# MWPR1516 register map
Vendor: Freescale Semiconductor, Inc.; Series: Kinetis; File version: 1.6
CPU: CM0PLUS r0p0, little endian, no MPU, no FPU, VTOR, 2 interrupt priority bits
Registers are 8-bit, read-write, reset 0x0 unless marked. A register's access mark holds for its fields unless they carry their own. Offsets are from the block's base; [hi:lo] are bit positions; {n}, {i} and the like mark numbered series.

## SIM — System Integration Module
Base 0x40048000; register names take the prefix SIM_
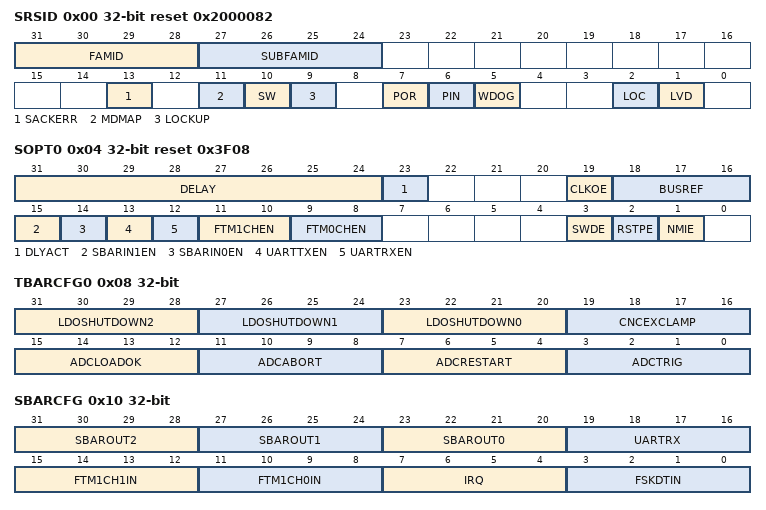
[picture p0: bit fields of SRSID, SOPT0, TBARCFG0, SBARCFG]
0x00 SRSID 32-bit ro reset 0x2000082 — System Reset Status and ID Register
  [31:28] FAMID — Wireless power controller Family ID
    0=Wireless power receiver (WPR); 1=Wireless charger receiver (WCR); 8=Wireless charger transmitter (WCT)
  [27:24] SUBFAMID — Wireless power controller Sub-family power ID
    0=1 W; 1=5 W; 2=15 W
  [13] SACKERR — Stop Mode Acknowledge Error Reset
    0=Reset is not caused by peripheral failure to acknowledge attempt to enter Stop mode; 1=Reset is caused by peripheral failure to acknowledge attempt to enter Stop mode
  [11] MDMAP — MDM-AP System Reset Request
    0=Reset is not caused by the host debugger system setting of the System Reset Request field; 1=Reset is caused by the host debugger system setting of the System Reset Request field
  [10] SW — Software
    0=Reset is not caused by software setting of the SYSRESETREQ bit; 1=Reset caused by software setting of the SYSRESETREQ bit
  [9] LOCKUP — Core Lockup
    0=Reset is not caused by core LOCKUP event; 1=Reset is caused by core LOCKUP event
  [7] POR — Power-on Reset
    0=Reset not caused by POR; 1=POR-caused reset
  [6] PIN — External Reset Pin
    0=Reset is not caused by external reset pin; 1=Reset originates from external reset pin
  [5] WDOG — Watchdog (WDOG)
    0=Reset is not caused by WDOG timeout; 1=Reset is caused by WDOG timeout
  [2] LOC — Internal Clock Source (ICS) Module Reset
    0=Reset is not caused by the ICS module; 1=Reset is caused by the ICS module
  [1] LVD — Low Voltage Detection
    0=Reset is not caused by LVD trip or POR; 1=Reset is caused by LVD trip or POR
0x04 SOPT0 32-bit reset 0x3F08 — System Options Register 0
  [31:24] DELAY — ADC external Trigger Delay
  [23] DLYACT ro — ADC external Trigger Delay Active
    0=The delay is inactive; 1=The delay is active
  [19] CLKOE — Bus Clock Output Enable
    0=Bus clock output is disabled on PTA2; 1=Bus clock output is enabled on PTA2
  [18:16] BUSREF — BUS Clock Output select
    0=Bus; 1=Bus divided by 2; 2=Bus divided by 4; 3=Bus divided by 8; 4=Bus divided by 16; 5=Bus divided by 32; 6=Bus divided by 64; 7=Bus divided by 128
  [15] SBARIN1EN
    0=SBAR_IN1 on PTA0 is disabled; 1=SBAR_IN1 on PTA0 is enabled
  [14] SBARIN0EN
    0=SBAR_IN0 on PTB1 is disabled; 1=SBAR_IN0 on PTB1 is enabled
  [13] UARTTXEN
    0=UART0_TX on PTA7 is disabled; 1=UART0_TX on PTA7 is enabled
  [12] UARTRXEN
    0=UART0_RX on PTA6 is disabled; 1=UART0_RX on PTA6 is enabled
  [11:10] FTM1CHEN — FTM1 Channel mapping Enable
  [9:8] FTM0CHEN — FTM0 Channel mapping Enable
  [3] SWDE — Single Wire Debug port pin mapping Enable
    0=SWDIO pin mapping on PTA4 is disabled, and SWCLK pin mapping on PTA5 is disabled; 1=PTA4 as SWDIO function, and PTA5 as SWCLK function
  [2] RSTPE — RESET Pin mapping Enable
    0=RESET pin mapping is disabled on PTB0; 1=PTB0 pin functions as RESET
  [1] NMIE — NMI pin mapping Enable
    0=NMIE pin mapping is disabled on PTB0; 1=PTB0 pin functions as NMI, when RSTPE = 0
0x08 TBARCFG0 32-bit — Trigger Crossbar Configuration Register 0
  [31:28] LDOSHUTDOWN2 — LDO external Shutdown source 2
  [27:24] LDOSHUTDOWN1 — LDO external Shutdown source 1
  [23:20] LDOSHUTDOWN0 — LDO external Shutdown source 0
  [19:16] CNCEXCLAMP — CNC External Clamp source selection
  [15:12] ADCLOADOK — ADC LoadOK source selection
  [11:8] ADCABORT — ADC sequence Abort source selection
  [7:4] ADCRESTART — ADC Restart source selection
  [3:0] ADCTRIG — ADC Trigger source selection
0x0C TBARCFG1 32-bit — Trigger Crossbar Configuration Register 1
  [3:0] TBAROUT — TBAR_OUT source selection
0x10 SBARCFG 32-bit — Signal Crossbar Configuration Register
  [31:28] SBAROUT2 — SBAR_OUT2 source selection
  [27:24] SBAROUT1 — SBAR_OUT1 source selection
  [23:20] SBAROUT0 — SBAR_OUT0 source selection
  [19:16] UARTRX — UART_RxD source selection
  [15:12] FTM1CH1IN — FTM1_CH1 Input source selection
  [11:8] FTM1CH0IN — FTM1_CH0 Input source selection
  [7:4] IRQ — IRQ input source selection
  [3:0] FSKDTIN — FSKDT Input source selection
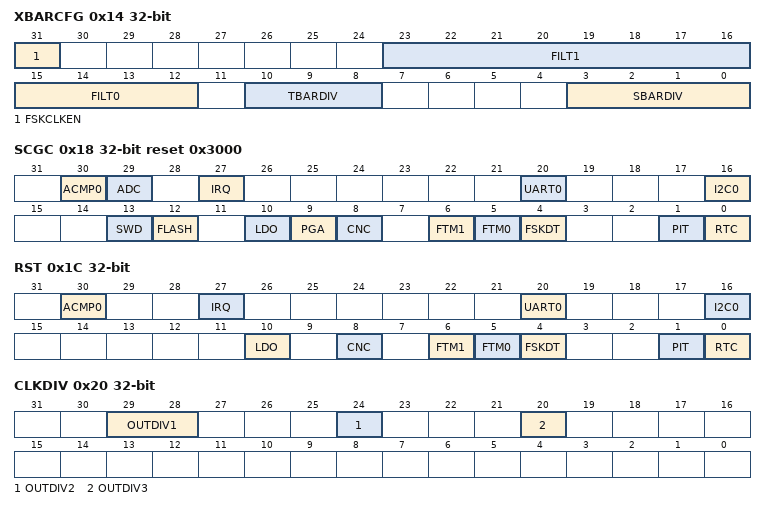
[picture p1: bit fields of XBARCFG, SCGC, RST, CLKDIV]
0x14 XBARCFG 32-bit — FSK Configuration Register
  [31] FSKCLKEN — FSK glitch filter and divider Clock Enable control
    0=Disables the FSK filter/divider clock; 1=Enables the FSK filter/divider clock
  [23:16] FILT1 — The second glitch filter width configuration control
  [15:12] FILT0 — The first glitch filter width configuration control
  [10:8] TBARDIV — TBAR FSK Divider source control
  [3:0] SBARDIV — SBAR FSK Divider source control
0x18 SCGC 32-bit reset 0x3000 — System Clock Gating Control Register
  [30] ACMP0 — ACMP0 Clock Gating Control
    0=Bus clock to the ACMP0 module is disabled; 1=Bus clock to the ACMP0 module is enabled
  [29] ADC — ADC Clock Gating Control
    0=Bus clock to the ADC module is disabled; 1=Bus clock to the ADC module is enabled
  [27] IRQ — IRQ Clock Gating Control
    0=Bus clock to the IRQ module is disabled; 1=Bus clock to the IRQ module is enabled
  [20] UART0 — UART0 Clock Gating Control
    0=Bus clock to the UART0 module is disabled; 1=Bus clock to the UART0 module is enabled
  [16] I2C0 — I2C0 Clock Gating Control
    0=Bus clock to the I2C0 module is disabled; 1=Bus clock to the I2C0 module is enabled
  [13] SWD — Single Wire Debugger (SWD) Clock Gating Control
    0=Bus clock to the SWD module is disabled; 1=Bus clock to the SWD module is enabled
  [12] FLASH — Flash Clock Gating Control
    0=Bus clock to the Flash module is disabled; 1=Bus clock to the Flash module is enabled
  [10] LDO — LDO Clock Gating Control
    0=Bus clock to the LDO module is disabled; 1=Bus clock to the LDO module is enabled
  [9] PGA — PGA Clock Gating Control
    0=Bus clock to the PGA module is disabled; 1=Bus clock to the PGA module is enabled
  [8] CNC — CNC Clock Gating Control
    0=Bus clock to the CNC module is disabled; 1=Bus clock to the CNC module is enabled
  [6] FTM1 — FTM1 Clock Gating Control
    0=Bus clock to the FTM1 module is disabled; 1=Bus clock to the FTM1 module is enabled
  [5] FTM0 — FTM0 Clock Gating Control
    0=Bus clock to the FTM0 module is disabled; 1=Bus clock to the FTM0 module is enabled
  [4] FSKDT — FSKDT Clock Gating Control
    0=Bus clock to the FSKDT module is disabled; 1=Bus clock to the FSKDT module is enabled
  [1] PIT — PIT Clock Gating Control
    0=Bus clock to the PIT module is disabled; 1=Bus clock to the PIT module is enabled
  [0] RTC — RTC Clock Gating Control
    0=Bus clock to the RTC module is disabled; 1=Bus clock to the RTC module is enabled
0x1C RST 32-bit — Reset control Register
  [30] ACMP0 — ACMP0 Reset Control
    0=Reset to the ACMP0 module is disabled; 1=Reset to the ACMP0 module is enabled
  [27] IRQ — IRQ Reset Control
    0=Reset to the IRQ module is disabled; 1=Reset to the IRQ module is enabled
  [20] UART0 — UART0 Reset Control
    0=Reset to the UART0 module is disabled; 1=Reset to the UART0 module is enabled
  [16] I2C0 — I2C0 Reset Control
    0=Reset to the I2C0 module is disabled; 1=Reset to the I2C0 module is enabled
  [10] LDO — LDO Reset Control
    0=Reset to the LDO module is disabled; 1=Reset to the LDO module is enabled
  [8] CNC — CNC Reset Control
    0=Reset to the CNC module is disabled; 1=Reset to the CNC module is enabled
  [6] FTM1 — FTM1 Reset Control
    0=Reset to the FTM1 module is disabled; 1=Reset to the FTM1 module is enabled
  [5] FTM0 — FTM0 Reset Control
    0=Reset to the FTM0 module is disabled; 1=Reset to the FTM0 module is enabled
  [4] FSKDT — FSKDT Reset Control
    0=Reset to the FSKDT module is disabled; 1=Reset to the FSKDT module is enabled
  [1] PIT — PIT Reset Control
    0=Reset to the PIT module is disabled; 1=Reset to the PIT module is enabled
  [0] RTC — RTC Reset Control
    0=Reset to the RTC module is disabled; 1=Reset to the RTC module is enabled
0x20 CLKDIV 32-bit — Clock Divider Register
  [29:28] OUTDIV1 — Clock 1 Output Divider value
    0=Same as ICSOUTCLK; 1=ICSOUTCLK is divided by 2; 2=ICSOUTCLK is divided by 3; 3=ICSOUTCLK is divided by 4
  [24] OUTDIV2 — Clock 2 Output Divider value
    0=Not divided from Divider1; 1=Divided by 2 from Divider1
  [20] OUTDIV3 — Clock 3 Output Divider value
    0=Same as ICSOUTCLK; 1=ICSOUTCLK is divided by 2
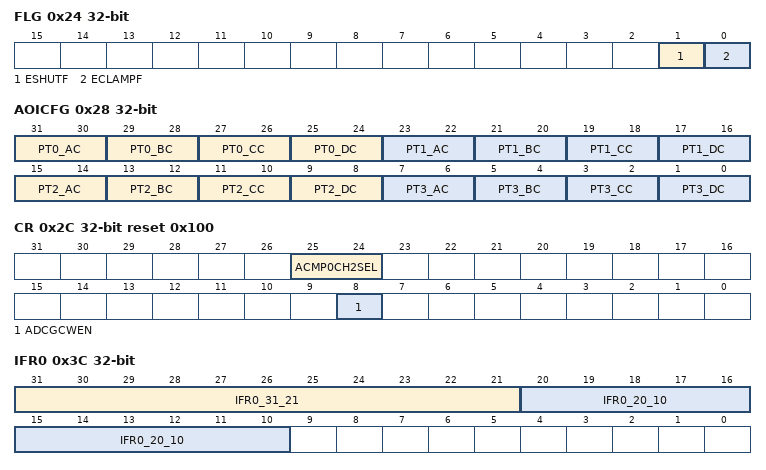
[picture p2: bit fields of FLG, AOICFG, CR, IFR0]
0x24 FLG 32-bit — CNC external clamp and LDO external shutdown Flags Register
  [1] ESHUTF — LDO External Shutdown status Flag
    0=LDO external shutdown is de-asserted; 1=LDO external shutdown is asserted. Write 1 to clear this flag.
  [0] ECLAMPF — CNC External Clamp status Flag
    0=CNC external clamp is de-asserted; 1=CNC external clamp is asserted. Write 1 to clear this flag.
0x28 AOICFG 32-bit — AOI function Configuration Register
  [31-8n:30-8n] PT{n}_AC (n=0..3) — Product Term {n}, A input Configuration
    0=Force the A input in this product term to a logic zero; 1=Pass the A input in this product term; 2=Complement the A input in this product term; 3=Force the A input in this product term to a logic one
  [29-8n:28-8n] PT{n}_BC (n=0..3) — Product Term {n}, B input Configuration
    0=Force the B input in this product term to a logic zero; 1=Pass the B input in this product term; 2=Complement the B input in this product term; 3=Force the B input in this product term to a logic one
  [27-8n:26-8n] PT{n}_CC (n=0..3) — Product Term {n}, C input Configuration
    0=Force the C input in this product term to a logic zero; 1=Pass the C input in this product term; 2=Complement the C input in this product term; 3=Force the C input in this product term to a logic one
  [25-8n:24-8n] PT{n}_DC (n=0..3) — Product Term {n}, D input Configuration
    0=Force the D input in this product term to a logic zero; 1=Pass the D input in this product term; 2=Complement the D input in this product term; 3=Force the D input in this product term to a logic one
0x2C CR 32-bit reset 0x100 — ACMP channel 2 Configuration and SIM_SCGC[ADC] write enable Register
  [25:24] ACMP0CH2SEL — ACMP0_IN[2] Selection
    0=AC1 divider output from CNC, the divider value depends on the CNC_ANACFG2[ACDIV], and output enable is controlled by CNC_ANACFG1[AC1DIVOE]; 1=1/5 AD_IN output from CNC, the output enable is controlled by CNC_ANACFG1[VADDIVOE]; 2=1/8 VREC output; 3=7/10 VOUT output from LDO, the output control is enabled by setting LDO_CR[LDOEN], LDO_CR[CPEN], LDO_CR[LDOREGEN], and LDO_CR[CPCLKPS] first and waiting LDO_SR[CPOKF] flag to be set
  [8] ADCGCWEN — ADC Clock Gating control bit Write Enable
    0=SIM_SCGC[ADC] cannot be changed; 1=SIM_SCGC[ADC] can be changed
0x30 UUIDL 32-bit ro reset not defined — Universally Unique Identifier Low Register
  [31:0] ID — Universally Unique Identifier
0x34 UUIDML 32-bit ro reset not defined — Universally Unique Identifier Middle Low Register
  [31:0] ID — Universally Unique Identifier
0x38 UUIDMH 32-bit ro reset not defined — Universally Unique Identifier Middle High Register
  [15:0] ID — Universally Unique Identifier
0x3C IFR0 32-bit ro reset not defined — Peripherals IFR bits Register 0
  [31:21] IFR0_31_21, [20:10] IFR0_20_10
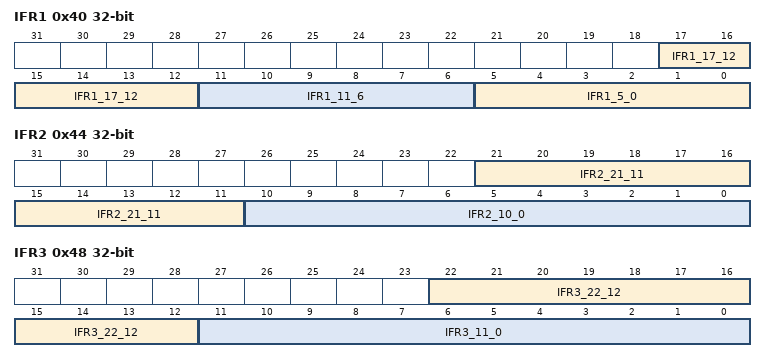
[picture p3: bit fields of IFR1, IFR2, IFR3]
0x40 IFR1 32-bit ro reset not defined — Peripherals IFR bits Register 1
  [17:12] IFR1_17_12, [11:6] IFR1_11_6, [5:0] IFR1_5_0
0x44 IFR2 32-bit ro reset not defined — Peripherals IFR bits Register 2
  [21:11] IFR2_21_11, [10:0] IFR2_10_0
0x48 IFR3 32-bit ro reset not defined — Peripherals IFR bits Register 3
  [22:12] IFR3_22_12, [11:0] IFR3_11_0
